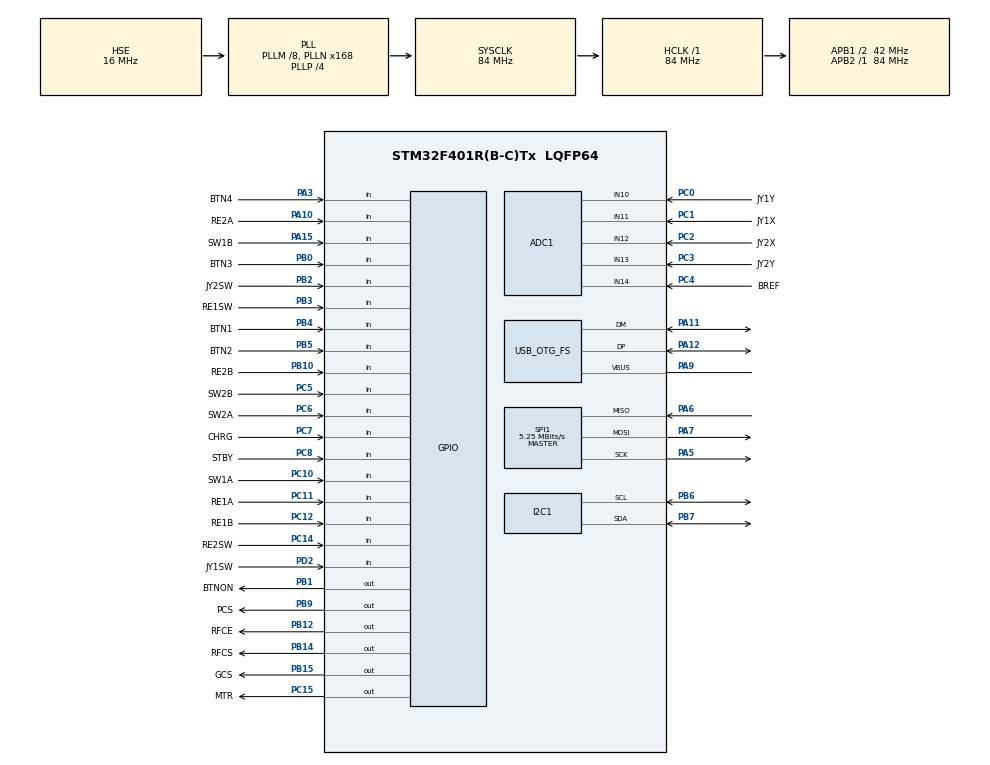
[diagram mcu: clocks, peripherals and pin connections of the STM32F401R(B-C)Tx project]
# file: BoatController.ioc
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ADC1.Channel-10\#ChannelRegularConversion=ADC_CHANNEL_11
ADC1.Channel-11\#ChannelRegularConversion=ADC_CHANNEL_12
ADC1.Channel-12\#ChannelRegularConversion=ADC_CHANNEL_13
ADC1.Channel-13\#ChannelRegularConversion=ADC_CHANNEL_14
ADC1.Channel-5\#ChannelRegularConversion=ADC_CHANNEL_10
ADC1.NbrOfConversion=5
ADC1.NbrOfConversionFlag=1
ADC1.Rank-10\#ChannelRegularConversion=2
ADC1.Rank-11\#ChannelRegularConversion=3
ADC1.Rank-12\#ChannelRegularConversion=4
ADC1.Rank-13\#ChannelRegularConversion=5
ADC1.Rank-5\#ChannelRegularConversion=1
ADC1.SamplingTime-10\#ChannelRegularConversion=ADC_SAMPLETIME_3CYCLES
ADC1.SamplingTime-11\#ChannelRegularConversion=ADC_SAMPLETIME_3CYCLES
ADC1.SamplingTime-12\#ChannelRegularConversion=ADC_SAMPLETIME_3CYCLES
ADC1.SamplingTime-13\#ChannelRegularConversion=ADC_SAMPLETIME_3CYCLES
ADC1.SamplingTime-5\#ChannelRegularConversion=ADC_SAMPLETIME_3CYCLES
ADC1.ScanConvMode=ENABLE
ADC1.master=1
Dma.ADC1.0.Direction=DMA_PERIPH_TO_MEMORY
Dma.ADC1.0.FIFOMode=DMA_FIFOMODE_DISABLE
Dma.ADC1.0.Instance=DMA2_Stream0
Dma.ADC1.0.MemDataAlignment=DMA_MDATAALIGN_HALFWORD
Dma.ADC1.0.MemInc=DMA_MINC_ENABLE
Dma.ADC1.0.Mode=DMA_NORMAL
Dma.ADC1.0.PeriphDataAlignment=DMA_PDATAALIGN_HALFWORD
Dma.ADC1.0.PeriphInc=DMA_PINC_DISABLE
Dma.ADC1.0.Priority=DMA_PRIORITY_LOW
Dma.Request0=ADC1
Mcu.Family=STM32F4
Mcu.Name=STM32F401R(B-C)Tx
Mcu.Package=LQFP64
NVIC.DMA2_Stream0_IRQn=true\:0\:0\:false\:false\:true\:false\:true\:true
NVIC.OTG_FS_IRQn=true\:0\:0\:false\:false\:true\:false\:true\:true
NVIC.PriorityGroup=NVIC_PRIORITYGROUP_4
NVIC.TIM1_TRG_COM_TIM11_IRQn=true\:0\:0\:false\:false\:true\:true\:true\:true
NVIC.TIM1_UP_TIM10_IRQn=true\:0\:0\:false\:false\:true\:true\:true\:true
PA10.GPIO_Label=RE2A
PA10.GPIO_PuPd=GPIO_PULLUP
PA10.Signal=GPIO_Input
PA11.Mode=Device_Only
PA11.Signal=USB_OTG_FS_DM
PA12.Mode=Device_Only
PA12.Signal=USB_OTG_FS_DP
PA13.Mode=Serial_Wire
PA13.Signal=SYS_JTMS-SWDIO
PA14.Mode=Serial_Wire
PA14.Signal=SYS_JTCK-SWCLK
PA15.GPIO_Label=SW1B
PA15.GPIO_PuPd=GPIO_PULLUP
PA15.Signal=GPIO_Input
PA3.GPIO_Label=BTN4
PA3.GPIO_PuPd=GPIO_PULLUP
PA3.Signal=GPIO_Input
PA5.Mode=Full_Duplex_Master
PA5.Signal=SPI1_SCK
PA6.Mode=Full_Duplex_Master
PA6.Signal=SPI1_MISO
PA7.Mode=Full_Duplex_Master
PA7.Signal=SPI1_MOSI
PA9.Mode=Activate_VBUS
PA9.Signal=USB_OTG_FS_VBUS
PB0.GPIO_Label=BTN3
PB0.GPIO_PuPd=GPIO_PULLUP
PB0.Signal=GPIO_Input
PB1.GPIO_Label=BTNON
PB1.GPIO_Speed=GPIO_SPEED_FREQ_MEDIUM
PB1.PinState=GPIO_PIN_SET
PB1.Signal=GPIO_Output
PB10.GPIO_Label=RE2B
PB10.GPIO_PuPd=GPIO_PULLUP
PB10.Signal=GPIO_Input
PB12.GPIO_Label=RFCE
PB12.GPIO_Speed=GPIO_SPEED_FREQ_VERY_HIGH
PB12.Signal=GPIO_Output
PB14.GPIO_Label=RFCS
PB14.GPIO_Speed=GPIO_SPEED_FREQ_VERY_HIGH
PB14.PinState=GPIO_PIN_SET
PB14.Signal=GPIO_Output
PB15.GPIO_Label=GCS
PB15.GPIO_Speed=GPIO_SPEED_FREQ_VERY_HIGH
PB15.PinState=GPIO_PIN_SET
PB15.Signal=GPIO_Output
PB2.GPIO_Label=JY2SW
PB2.GPIO_PuPd=GPIO_PULLUP
PB2.Signal=GPIO_Input
PB3.GPIO_Label=RE1SW
PB3.GPIO_PuPd=GPIO_PULLUP
PB3.Signal=GPIO_Input
PB4.GPIO_Label=BTN1
PB4.GPIO_PuPd=GPIO_PULLUP
PB4.Signal=GPIO_Input
PB5.GPIO_Label=BTN2
PB5.GPIO_PuPd=GPIO_PULLUP
PB5.Signal=GPIO_Input
PB6.Mode=I2C
PB6.Signal=I2C1_SCL
PB7.Mode=I2C
PB7.Signal=I2C1_SDA
PB9.GPIO_Label=PCS
PB9.GPIO_Speed=GPIO_SPEED_FREQ_VERY_HIGH
PB9.PinState=GPIO_PIN_SET
PB9.Signal=GPIO_Output
PC0.GPIO_Label=JY1Y
PC0.Signal=ADCx_IN10
PC1.GPIO_Label=JY1X
PC1.Signal=ADCx_IN11
PC10.GPIO_Label=SW1A
PC10.GPIO_PuPd=GPIO_PULLUP
PC10.Signal=GPIO_Input
PC11.GPIO_Label=RE1A
PC11.GPIO_PuPd=GPIO_PULLUP
PC11.Signal=GPIO_Input
PC12.GPIO_Label=RE1B
PC12.GPIO_PuPd=GPIO_PULLUP
PC12.Signal=GPIO_Input
PC14-OSC32_IN.GPIO_Label=RE2SW
PC14-OSC32_IN.GPIO_PuPd=GPIO_PULLUP
PC14-OSC32_IN.Signal=GPIO_Input
PC15-OSC32_OUT.GPIO_Label=MTR
PC15-OSC32_OUT.GPIO_PuPd=GPIO_NOPULL
PC15-OSC32_OUT.GPIO_Speed=GPIO_SPEED_FREQ_LOW
PC15-OSC32_OUT.PinState=GPIO_PIN_SET
PC15-OSC32_OUT.Signal=GPIO_Output
PC2.GPIO_Label=JY2X
PC2.Signal=ADCx_IN12
PC3.GPIO_Label=JY2Y
PC3.Signal=ADCx_IN13
PC4.GPIO_Label=BREF
PC4.Signal=ADCx_IN14
PC5.GPIO_Label=SW2B
PC5.GPIO_PuPd=GPIO_PULLUP
PC5.Signal=GPIO_Input
PC6.GPIO_Label=SW2A
PC6.GPIO_PuPd=GPIO_PULLUP
PC6.Signal=GPIO_Input
PC7.GPIO_Label=CHRG
PC7.GPIO_PuPd=GPIO_PULLUP
PC7.Signal=GPIO_Input
PC8.GPIO_Label=STBY
PC8.GPIO_PuPd=GPIO_PULLUP
PC8.Signal=GPIO_Input
PD2.GPIO_Label=JY1SW
PD2.GPIO_PuPd=GPIO_PULLUP
PD2.Signal=GPIO_Input
PH0\ -\ OSC_IN.Mode=HSE-External-Oscillator
PH0\ -\ OSC_IN.Signal=RCC_OSC_IN
PH1\ -\ OSC_OUT.Mode=HSE-External-Oscillator
PH1\ -\ OSC_OUT.Signal=RCC_OSC_OUT
ProjectManager.HeapSize=0x200
ProjectManager.StackSize=0x400
ProjectManager.TargetToolchain=STM32CubeIDE
RCC.48MHZClocksFreq_Value=48000000
RCC.AHBFreq_Value=84000000
RCC.APB1CLKDivider=RCC_HCLK_DIV2
RCC.APB1Freq_Value=42000000
RCC.APB1TimFreq_Value=84000000
RCC.APB2Freq_Value=84000000
RCC.APB2TimFreq_Value=84000000
RCC.CortexFreq_Value=84000000
RCC.HCLKFreq_Value=84000000
RCC.HSE_VALUE=16000000
RCC.HSI_VALUE=16000000
RCC.LSE_VALUE=32768
RCC.PLLM=8
RCC.PLLN=168
RCC.PLLP=RCC_PLLP_DIV4
RCC.PLLQ=7
RCC.SYSCLKFreq_VALUE=84000000
RCC.SYSCLKSource=RCC_SYSCLKSOURCE_PLLCLK
RCC.VCOOutputFreq_Value=336000000
SH.ADCx_IN10.0=ADC1_IN10,IN10
SH.ADCx_IN11.0=ADC1_IN11,IN11
SH.ADCx_IN12.0=ADC1_IN12,IN12
SH.ADCx_IN13.0=ADC1_IN13,IN13
SH.ADCx_IN14.0=ADC1_IN14,IN14
SPI1.BaudRatePrescaler=SPI_BAUDRATEPRESCALER_16
SPI1.CalculateBaudRate=5.25 MBits/s
SPI1.Direction=SPI_DIRECTION_2LINES
SPI1.Mode=SPI_MODE_MASTER
SPI1.VirtualType=VM_MASTER
TIM10.Period=1000-1
TIM10.Prescaler=840-1
TIM11.Period=100-1
TIM11.Prescaler=84-1
USB_DEVICE.CLASS_NAME_FS=CDC
USB_DEVICE.VirtualMode=Cdc
USB_DEVICE.VirtualModeFS=Cdc_FS
USB_OTG_FS.VirtualMode=Device_Only
VP_TIM10_VS_ClockSourceINT.Mode=Enable_Timer
VP_TIM11_VS_ClockSourceINT.Mode=Enable_Timer
VP_USB_DEVICE_VS_USB_DEVICE_CDC_FS.Mode=CDC_FS
board=custom

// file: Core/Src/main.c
/* USER CODE BEGIN Header */
/**
 ******************************************************************************
 * @file           : main.c
 * @brief          : Main program body
 ******************************************************************************
 * @attention
 *
 * Copyright (c) 2024 STMicroelectronics.
 * All rights reserved.
 *
 * This software is licensed under terms that can be found in the LICENSE file
 * in the root directory of this software component.
 * If no LICENSE file comes with this software, it is provided AS-IS.
 *
 ******************************************************************************
 */
/* USER CODE END Header */
#include "main.h"
#include "usb_device.h"

/* USER CODE BEGIN Includes */
#include "control.h"
/* USER CODE END Includes */

ADC_HandleTypeDef hadc1;
DMA_HandleTypeDef hdma_adc1;

I2C_HandleTypeDef hi2c1;

SPI_HandleTypeDef hspi1;

TIM_HandleTypeDef htim10;
TIM_HandleTypeDef htim11;

void SystemClock_Config(void);
static void MX_GPIO_Init(void);
static void MX_DMA_Init(void);
static void MX_I2C1_Init(void);
static void MX_ADC1_Init(void);
static void MX_SPI1_Init(void);
static void MX_TIM10_Init(void);
static void MX_TIM11_Init(void);

int main(void)
{

  /* MCU Configuration--------------------------------------------------------*/

  /* Reset of all peripherals, Initializes the Flash interface and the Systick. */
  HAL_Init();

  /* Configure the system clock */
  SystemClock_Config();

  /* Initialize all configured peripherals */
  MX_GPIO_Init();
  MX_DMA_Init();
  MX_I2C1_Init();
  MX_USB_DEVICE_Init();
  MX_ADC1_Init();
  MX_SPI1_Init();
  MX_TIM10_Init();
  MX_TIM11_Init();
  /* USER CODE BEGIN 2 */
	Control_Init();
  /* USER CODE END 2 */

  /* Infinite loop */
  /* USER CODE BEGIN WHILE */
	while (1) {
		Control_Loop();
    /* USER CODE END WHILE */

	}
}

void SystemClock_Config(void)
{
  RCC_OscInitTypeDef RCC_OscInitStruct = {0};
  RCC_ClkInitTypeDef RCC_ClkInitStruct = {0};

  /** Configure the main internal regulator output voltage
  */
  __HAL_RCC_PWR_CLK_ENABLE();
  __HAL_PWR_VOLTAGESCALING_CONFIG(PWR_REGULATOR_VOLTAGE_SCALE2);

  /** Initializes the RCC Oscillators according to the specified parameters
  * in the RCC_OscInitTypeDef structure.
  */
  RCC_OscInitStruct.OscillatorType = RCC_OSCILLATORTYPE_HSE;
  RCC_OscInitStruct.HSEState = RCC_HSE_ON;
  RCC_OscInitStruct.PLL.PLLState = RCC_PLL_ON;
  RCC_OscInitStruct.PLL.PLLSource = RCC_PLLSOURCE_HSE;
  RCC_OscInitStruct.PLL.PLLM = 8;
  RCC_OscInitStruct.PLL.PLLN = 168;
  RCC_OscInitStruct.PLL.PLLP = RCC_PLLP_DIV4;
  RCC_OscInitStruct.PLL.PLLQ = 7;
  if (HAL_RCC_OscConfig(&RCC_OscInitStruct) != HAL_OK)
  {
    Error_Handler();
  }

  /** Initializes the CPU, AHB and APB buses clocks
  */
  RCC_ClkInitStruct.ClockType = RCC_CLOCKTYPE_HCLK|RCC_CLOCKTYPE_SYSCLK
                              |RCC_CLOCKTYPE_PCLK1|RCC_CLOCKTYPE_PCLK2;
  RCC_ClkInitStruct.SYSCLKSource = RCC_SYSCLKSOURCE_PLLCLK;
  RCC_ClkInitStruct.AHBCLKDivider = RCC_SYSCLK_DIV1;
  RCC_ClkInitStruct.APB1CLKDivider = RCC_HCLK_DIV2;
  RCC_ClkInitStruct.APB2CLKDivider = RCC_HCLK_DIV1;

  if (HAL_RCC_ClockConfig(&RCC_ClkInitStruct, FLASH_LATENCY_2) != HAL_OK)
  {
    Error_Handler();
  }
}

static void MX_ADC1_Init(void)
{

  ADC_ChannelConfTypeDef sConfig = {0};

  /** Configure the global features of the ADC (Clock, Resolution, Data Alignment and number of conversion)
  */
  hadc1.Instance = ADC1;
  hadc1.Init.ClockPrescaler = ADC_CLOCK_SYNC_PCLK_DIV4;
  hadc1.Init.Resolution = ADC_RESOLUTION_12B;
  hadc1.Init.ScanConvMode = ENABLE;
  hadc1.Init.ContinuousConvMode = DISABLE;
  hadc1.Init.DiscontinuousConvMode = DISABLE;
  hadc1.Init.ExternalTrigConvEdge = ADC_EXTERNALTRIGCONVEDGE_NONE;
  hadc1.Init.ExternalTrigConv = ADC_SOFTWARE_START;
  hadc1.Init.DataAlign = ADC_DATAALIGN_RIGHT;
  hadc1.Init.NbrOfConversion = 5;
  hadc1.Init.DMAContinuousRequests = DISABLE;
  hadc1.Init.EOCSelection = ADC_EOC_SINGLE_CONV;
  if (HAL_ADC_Init(&hadc1) != HAL_OK)
  {
    Error_Handler();
  }

  /** Configure for the selected ADC regular channel its corresponding rank in the sequencer and its sample time.
  */
  sConfig.Channel = ADC_CHANNEL_10;
  sConfig.Rank = 1;
  sConfig.SamplingTime = ADC_SAMPLETIME_3CYCLES;
  if (HAL_ADC_ConfigChannel(&hadc1, &sConfig) != HAL_OK)
  {
    Error_Handler();
  }

  /** Configure for the selected ADC regular channel its corresponding rank in the sequencer and its sample time.
  */
  sConfig.Channel = ADC_CHANNEL_11;
  sConfig.Rank = 2;
  if (HAL_ADC_ConfigChannel(&hadc1, &sConfig) != HAL_OK)
  {
    Error_Handler();
  }

  /** Configure for the selected ADC regular channel its corresponding rank in the sequencer and its sample time.
  */
  sConfig.Channel = ADC_CHANNEL_12;
  sConfig.Rank = 3;
  if (HAL_ADC_ConfigChannel(&hadc1, &sConfig) != HAL_OK)
  {
    Error_Handler();
  }

  /** Configure for the selected ADC regular channel its corresponding rank in the sequencer and its sample time.
  */
  sConfig.Channel = ADC_CHANNEL_13;
  sConfig.Rank = 4;
  if (HAL_ADC_ConfigChannel(&hadc1, &sConfig) != HAL_OK)
  {
    Error_Handler();
  }

  /** Configure for the selected ADC regular channel its corresponding rank in the sequencer and its sample time.
  */
  sConfig.Channel = ADC_CHANNEL_14;
  sConfig.Rank = 5;
  if (HAL_ADC_ConfigChannel(&hadc1, &sConfig) != HAL_OK)
  {
    Error_Handler();
  }

}

static void MX_I2C1_Init(void)
{

  hi2c1.Instance = I2C1;
  hi2c1.Init.ClockSpeed = 100000;
  hi2c1.Init.DutyCycle = I2C_DUTYCYCLE_2;
  hi2c1.Init.OwnAddress1 = 0;
  hi2c1.Init.AddressingMode = I2C_ADDRESSINGMODE_7BIT;
  hi2c1.Init.DualAddressMode = I2C_DUALADDRESS_DISABLE;
  hi2c1.Init.OwnAddress2 = 0;
  hi2c1.Init.GeneralCallMode = I2C_GENERALCALL_DISABLE;
  hi2c1.Init.NoStretchMode = I2C_NOSTRETCH_DISABLE;
  if (HAL_I2C_Init(&hi2c1) != HAL_OK)
  {
    Error_Handler();
  }

}

static void MX_SPI1_Init(void)
{

  /* SPI1 parameter configuration*/
  hspi1.Instance = SPI1;
  hspi1.Init.Mode = SPI_MODE_MASTER;
  hspi1.Init.Direction = SPI_DIRECTION_2LINES;
  hspi1.Init.DataSize = SPI_DATASIZE_8BIT;
  hspi1.Init.CLKPolarity = SPI_POLARITY_LOW;
  hspi1.Init.CLKPhase = SPI_PHASE_1EDGE;
  hspi1.Init.NSS = SPI_NSS_SOFT;
  hspi1.Init.BaudRatePrescaler = SPI_BAUDRATEPRESCALER_16;
  hspi1.Init.FirstBit = SPI_FIRSTBIT_MSB;
  hspi1.Init.TIMode = SPI_TIMODE_DISABLE;
  hspi1.Init.CRCCalculation = SPI_CRCCALCULATION_DISABLE;
  hspi1.Init.CRCPolynomial = 10;
  if (HAL_SPI_Init(&hspi1) != HAL_OK)
  {
    Error_Handler();
  }

}

static void MX_TIM10_Init(void)
{

  htim10.Instance = TIM10;
  htim10.Init.Prescaler = 840-1;
  htim10.Init.CounterMode = TIM_COUNTERMODE_UP;
  htim10.Init.Period = 1000-1;
  htim10.Init.ClockDivision = TIM_CLOCKDIVISION_DIV1;
  htim10.Init.AutoReloadPreload = TIM_AUTORELOAD_PRELOAD_DISABLE;
  if (HAL_TIM_Base_Init(&htim10) != HAL_OK)
  {
    Error_Handler();
  }

}

static void MX_TIM11_Init(void)
{

  htim11.Instance = TIM11;
  htim11.Init.Prescaler = 84-1;
  htim11.Init.CounterMode = TIM_COUNTERMODE_UP;
  htim11.Init.Period = 100-1;
  htim11.Init.ClockDivision = TIM_CLOCKDIVISION_DIV1;
  htim11.Init.AutoReloadPreload = TIM_AUTORELOAD_PRELOAD_DISABLE;
  if (HAL_TIM_Base_Init(&htim11) != HAL_OK)
  {
    Error_Handler();
  }

}

static void MX_DMA_Init(void)
{

  /* DMA controller clock enable */
  __HAL_RCC_DMA2_CLK_ENABLE();

  /* DMA interrupt init */
  /* DMA2_Stream0_IRQn interrupt configuration */
  HAL_NVIC_SetPriority(DMA2_Stream0_IRQn, 0, 0);
  HAL_NVIC_EnableIRQ(DMA2_Stream0_IRQn);

}

static void MX_GPIO_Init(void)
{
  GPIO_InitTypeDef GPIO_InitStruct = {0};

  /* GPIO Ports Clock Enable */
  __HAL_RCC_GPIOC_CLK_ENABLE();
  __HAL_RCC_GPIOH_CLK_ENABLE();
  __HAL_RCC_GPIOA_CLK_ENABLE();
  __HAL_RCC_GPIOB_CLK_ENABLE();
  __HAL_RCC_GPIOD_CLK_ENABLE();

  /*Configure GPIO pin Output Level */
  HAL_GPIO_WritePin(MTR_GPIO_Port, MTR_Pin, GPIO_PIN_SET);

  /*Configure GPIO pin Output Level */
  HAL_GPIO_WritePin(GPIOB, BTNON_Pin|RFCS_Pin|GCS_Pin|PCS_Pin, GPIO_PIN_SET);

  /*Configure GPIO pin Output Level */
  HAL_GPIO_WritePin(RFCE_GPIO_Port, RFCE_Pin, GPIO_PIN_RESET);

  /*Configure GPIO pins : RE2SW_Pin SW2B_Pin SW2A_Pin CHRG_Pin
                           STBY_Pin SW1A_Pin RE1A_Pin RE1B_Pin */
  GPIO_InitStruct.Pin = RE2SW_Pin|SW2B_Pin|SW2A_Pin|CHRG_Pin
                          |STBY_Pin|SW1A_Pin|RE1A_Pin|RE1B_Pin;
  GPIO_InitStruct.Mode = GPIO_MODE_INPUT;
  GPIO_InitStruct.Pull = GPIO_PULLUP;
  HAL_GPIO_Init(GPIOC, &GPIO_InitStruct);

  /*Configure GPIO pin : MTR_Pin */
  GPIO_InitStruct.Pin = MTR_Pin;
  GPIO_InitStruct.Mode = GPIO_MODE_OUTPUT_PP;
  GPIO_InitStruct.Pull = GPIO_NOPULL;
  GPIO_InitStruct.Speed = GPIO_SPEED_FREQ_LOW;
  HAL_GPIO_Init(MTR_GPIO_Port, &GPIO_InitStruct);

  /*Configure GPIO pins : BTN4_Pin RE2A_Pin SW1B_Pin */
  GPIO_InitStruct.Pin = BTN4_Pin|RE2A_Pin|SW1B_Pin;
  GPIO_InitStruct.Mode = GPIO_MODE_INPUT;
  GPIO_InitStruct.Pull = GPIO_PULLUP;
  HAL_GPIO_Init(GPIOA, &GPIO_InitStruct);

  /*Configure GPIO pins : BTN3_Pin JY2SW_Pin RE2B_Pin RE1SW_Pin
                           BTN1_Pin BTN2_Pin */
  GPIO_InitStruct.Pin = BTN3_Pin|JY2SW_Pin|RE2B_Pin|RE1SW_Pin
                          |BTN1_Pin|BTN2_Pin;
  GPIO_InitStruct.Mode = GPIO_MODE_INPUT;
  GPIO_InitStruct.Pull = GPIO_PULLUP;
  HAL_GPIO_Init(GPIOB, &GPIO_InitStruct);

  /*Configure GPIO pin : BTNON_Pin */
  GPIO_InitStruct.Pin = BTNON_Pin;
  GPIO_InitStruct.Mode = GPIO_MODE_OUTPUT_PP;
  GPIO_InitStruct.Pull = GPIO_NOPULL;
  GPIO_InitStruct.Speed = GPIO_SPEED_FREQ_MEDIUM;
  HAL_GPIO_Init(BTNON_GPIO_Port, &GPIO_InitStruct);

  /*Configure GPIO pins : RFCE_Pin RFCS_Pin GCS_Pin PCS_Pin */
  GPIO_InitStruct.Pin = RFCE_Pin|RFCS_Pin|GCS_Pin|PCS_Pin;
  GPIO_InitStruct.Mode = GPIO_MODE_OUTPUT_PP;
  GPIO_InitStruct.Pull = GPIO_NOPULL;
  GPIO_InitStruct.Speed = GPIO_SPEED_FREQ_VERY_HIGH;
  HAL_GPIO_Init(GPIOB, &GPIO_InitStruct);

  /*Configure GPIO pin : JY1SW_Pin */
  GPIO_InitStruct.Pin = JY1SW_Pin;
  GPIO_InitStruct.Mode = GPIO_MODE_INPUT;
  GPIO_InitStruct.Pull = GPIO_PULLUP;
  HAL_GPIO_Init(JY1SW_GPIO_Port, &GPIO_InitStruct);

}

void Error_Handler(void)
{
	__disable_irq();
	while (1) {
	}
}
